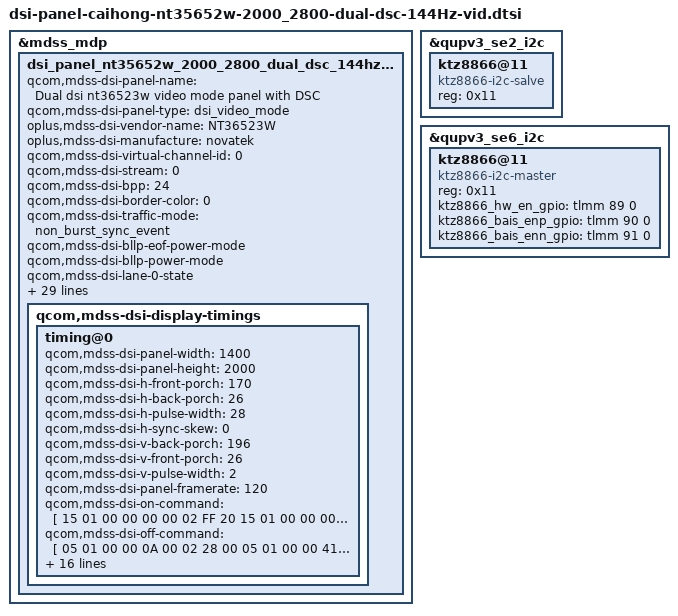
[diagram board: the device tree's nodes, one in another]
&mdss_mdp {
	dsi_panel_nt35652w_2000_2800_dual_dsc_144hz_vid: qcom,mdss_dsi_panel_nt35652w_2000_2800_dual_dsc_144hz_vid {
		qcom,mdss-dsi-panel-name = "Dual dsi nt36523w video mode panel with DSC";
		qcom,mdss-dsi-panel-type = "dsi_video_mode";
		oplus,mdss-dsi-vendor-name = "NT36523W";
		oplus,mdss-dsi-manufacture = "novatek";
		qcom,mdss-dsi-virtual-channel-id = <0>;
		qcom,mdss-dsi-stream = <0>;
		qcom,mdss-dsi-bpp = <24>;
		qcom,mdss-dsi-border-color = <0>;
		qcom,mdss-dsi-traffic-mode = "non_burst_sync_event";
		qcom,mdss-dsi-bllp-eof-power-mode;
		qcom,mdss-dsi-bllp-power-mode;
		qcom,mdss-dsi-lane-0-state;
		qcom,mdss-dsi-lane-1-state;
		qcom,mdss-dsi-lane-2-state;
		qcom,mdss-dsi-lane-3-state;
		qcom,mdss-dsi-dma-trigger = "trigger_sw";
		qcom,mdss-dsi-mdp-trigger = "none";
		qcom,mdss-dsi-tx-eot-append;
		qcom,mdss-dsi-reset-sequence = <1 10>, <0 5>, <1 10>;
		qcom,mdss-pan-physical-width-dimension = <240>;
		qcom,mdss-pan-physical-height-dimension = <171>;

		qcom,mdss-dsi-display-timings {
			timing@0 {
				qcom,mdss-dsi-panel-width = <1400>;
				qcom,mdss-dsi-panel-height = <2000>;
				qcom,mdss-dsi-h-front-porch = <170>;
				qcom,mdss-dsi-h-back-porch = <26>;
				qcom,mdss-dsi-h-pulse-width = <28>;
				qcom,mdss-dsi-h-sync-skew = <0>;
				qcom,mdss-dsi-v-back-porch = <196>;
				qcom,mdss-dsi-v-front-porch = <26>;
				qcom,mdss-dsi-v-pulse-width = <2>;
				qcom,mdss-dsi-panel-framerate = <120>;

				qcom,mdss-dsi-on-command = [
					15 01 00 00 00 00 02 FF 20
					15 01 00 00 00 00 02 FB 01
					15 01 00 00 00 00 02 62 36
					15 01 00 00 00 00 02 63 A4
					15 01 00 00 00 00 02 7C 22
					15 01 00 00 00 00 02 FF 23
					15 01 00 00 00 00 02 FB 01
					15 01 00 00 00 00 02 00 60
					15 01 00 00 00 00 02 07 20
					15 01 00 00 00 00 02 08 01
					15 01 00 00 00 00 02 09 5A
					15 01 00 00 00 00 02 10 0C
					15 01 00 00 00 00 02 11 03
					15 01 00 00 00 00 02 12 6B
					15 01 00 00 00 00 02 15 03
					15 01 00 00 00 00 02 16 10
					15 01 00 00 00 00 02 0A 8E
					15 01 00 00 00 00 02 0B 8E
					15 01 00 00 00 00 02 0C 8E
					15 01 00 00 00 00 02 0D 00
					15 01 00 00 00 00 02 19 00
					15 01 00 00 00 00 02 1A 04
					15 01 00 00 00 00 02 1B 08
					15 01 00 00 00 00 02 1C 0C
					15 01 00 00 00 00 02 1D 10
					15 01 00 00 00 00 02 1E 14
					15 01 00 00 00 00 02 1F 18
					15 01 00 00 00 00 02 20 1C
					15 01 00 00 00 00 02 21 20
					15 01 00 00 00 00 02 22 24
					15 01 00 00 00 00 02 23 28
					15 01 00 00 00 00 02 24 2C
					15 01 00 00 00 00 02 25 30
					15 01 00 00 00 00 02 26 34
					15 01 00 00 00 00 02 27 38
					15 01 00 00 00 00 02 28 3C
					15 01 00 00 00 00 02 2A 20
					15 01 00 00 00 00 02 2B 20
					15 01 00 00 00 00 02 30 FF
					15 01 00 00 00 00 02 31 FD
					15 01 00 00 00 00 02 32 FC
					15 01 00 00 00 00 02 33 FA
					15 01 00 00 00 00 02 34 F8
					15 01 00 00 00 00 02 35 F6
					15 01 00 00 00 00 02 36 F4
					15 01 00 00 00 00 02 37 F2
					15 01 00 00 00 00 02 38 F0
					15 01 00 00 00 00 02 39 EE
					15 01 00 00 00 00 02 3A EC
					15 01 00 00 00 00 02 3B EA
					15 01 00 00 00 00 02 3D E9
					15 01 00 00 00 00 02 3F E8
					15 01 00 00 00 00 02 40 E7
					15 01 00 00 00 00 02 41 E6
					15 01 00 00 00 00 02 45 FF
					15 01 00 00 00 00 02 46 F9
					15 01 00 00 00 00 02 47 F6
					15 01 00 00 00 00 02 48 F2
					15 01 00 00 00 00 02 49 F0
					15 01 00 00 00 00 02 4A EC
					15 01 00 00 00 00 02 4B E8
					15 01 00 00 00 00 02 4C E4
					15 01 00 00 00 00 02 4D E0
					15 01 00 00 00 00 02 4E DE
					15 01 00 00 00 00 02 4F D9
					15 01 00 00 00 00 02 50 D6
					15 01 00 00 00 00 02 51 D4
					15 01 00 00 00 00 02 52 C2
					15 01 00 00 00 00 02 53 D0
					15 01 00 00 00 00 02 54 CD
					15 01 00 00 00 00 02 58 FF
					15 01 00 00 00 00 02 59 F6
					15 01 00 00 00 00 02 5A F0
					15 01 00 00 00 00 02 5B EB
					15 01 00 00 00 00 02 5C E8
					15 01 00 00 00 00 02 5D E5
					15 01 00 00 00 00 02 5E E3
					15 01 00 00 00 00 02 5F E0
					15 01 00 00 00 00 02 60 DE
					15 01 00 00 00 00 02 61 DA
					15 01 00 00 00 00 02 62 D7
					15 01 00 00 00 00 02 63 D4
					15 01 00 00 00 00 02 64 D2
					15 01 00 00 00 00 02 65 D0
					15 01 00 00 00 00 02 66 CC
					15 01 00 00 00 00 02 67 C8
					15 01 00 00 00 00 02 FF 24
					15 01 00 00 00 00 02 FB 01
					15 01 00 00 00 00 02 1C 80
					15 01 00 00 00 00 02 3A 58
					15 01 00 00 00 00 02 3B 58
					15 01 00 00 00 00 02 5A 02
					15 01 00 00 00 00 02 5B 52
					39 01 00 00 00 00 03 5E 00 04
					39 01 00 00 00 00 04 92 64 01 0D
					15 01 00 00 00 00 02 98 80
					15 01 00 00 00 00 02 DB 73
					15 01 00 00 00 00 02 DE 08
					15 01 00 00 00 00 02 FF 25
					15 01 00 00 00 00 02 FB 01
					15 01 00 00 00 00 02 05 00
					15 01 00 00 00 00 02 1F 02
					15 01 00 00 00 00 02 20 52
					15 01 00 00 00 00 02 23 09
					15 01 00 00 00 00 02 24 1D
					15 01 00 00 00 00 02 26 02
					15 01 00 00 00 00 02 27 52
					15 01 00 00 00 00 02 2A 09
					15 01 00 00 00 00 02 2B 1D
					15 01 00 00 00 00 02 31 20
					15 01 00 00 00 00 02 3A 01
					15 01 00 00 00 00 02 42 0B
					15 01 00 00 00 00 02 68 04
					15 01 00 00 00 00 02 6A 00
					15 01 00 00 00 00 02 C0 0C
					15 01 00 00 00 00 02 C2 A5
					15 01 00 00 00 00 02 FF 26
					15 01 00 00 00 00 02 FB 01
					15 01 00 00 00 00 02 04 74
					39 01 00 00 00 00 05 19 1F 1E 1F 1F
					39 01 00 00 00 00 05 1A E5 C1 E5 E5
					39 01 00 00 00 00 05 1B 1F 1D 1F 1F
					39 01 00 00 00 00 05 1C 04 E1 04 04
					15 01 00 00 00 00 02 1E 64
					15 01 00 00 00 00 02 1F 64
					39 01 00 00 00 00 05 2A 1F 1E 1F 1F
					39 01 00 00 00 00 05 2B DC B9 DC DC
					15 01 00 00 00 00 02 2F 0B
					15 01 00 00 00 00 02 30 64
					15 01 00 00 00 00 02 32 64
					15 01 00 00 00 00 02 33 22
					15 01 00 00 00 00 02 34 92
					15 01 00 00 00 00 02 35 78
					15 01 00 00 00 00 02 36 96
					15 01 00 00 00 00 02 37 78
					15 01 00 00 00 00 02 38 06
					15 01 00 00 00 00 02 3A 64
					39 01 00 00 00 00 04 3D 00 A0 2A
					15 01 00 00 00 00 02 40 64
					15 01 00 00 00 00 02 41 64
					15 01 00 00 00 00 02 42 64
					15 01 00 00 00 00 02 45 0B
					15 01 00 00 00 00 02 46 64
					15 01 00 00 00 00 02 48 64
					15 01 00 00 00 00 02 4A 64
					15 01 00 00 00 00 02 4D 58
					15 01 00 00 00 00 02 4E 58
					15 01 00 00 00 00 02 51 02
					15 01 00 00 00 00 02 52 52
					15 01 00 00 00 00 02 56 02
					15 01 00 00 00 00 02 58 52
					15 01 00 00 00 00 02 5B 02
					15 01 00 00 00 00 02 5C 52
					39 01 00 00 00 00 04 84 1D 1D 1D
					39 01 00 00 00 00 05 99 23 23 23 23
					39 01 00 00 00 00 05 9A 97 97 97 97
					39 01 00 00 00 00 05 9B 22 22 22 22
					39 01 00 00 00 00 05 9C B5 B5 B5 B5
					39 01 00 00 00 00 05 9D 23 23 23 23
					39 01 00 00 00 00 05 9E 8D 8D 8D 8D
					15 01 00 00 00 00 02 A7 08
					15 01 00 00 00 00 02 FF 27
					15 01 00 00 00 00 02 FB 01
					15 01 00 00 00 00 02 30 F0
					15 01 00 00 00 00 02 31 2A
					15 01 00 00 00 00 02 76 F0
					15 01 00 00 00 00 02 77 02
					15 01 00 00 00 00 02 79 13
					39 01 00 00 00 00 03 80 C0 08
					39 01 00 00 00 00 03 81 2D 00
					39 01 00 00 00 00 03 82 A5 80
					39 01 00 00 00 00 03 84 5F 00
					39 01 00 00 00 00 03 85 28 00
					39 01 00 00 00 00 03 86 A5 80
					39 01 00 00 00 00 03 88 5F 00
					15 01 00 00 00 00 02 96 F0
					15 01 00 00 00 00 02 97 2A
					15 01 00 00 00 00 02 FF 2A
					15 01 00 00 00 00 02 FB 01
					15 01 00 00 00 00 02 14 09
					15 01 00 00 00 00 02 1E 09
					15 01 00 00 00 00 02 1F 09
					15 01 00 00 00 00 02 64 36
					15 01 00 00 00 00 02 67 3E
					15 01 00 00 00 00 02 6A 36
					15 01 00 00 00 00 02 6D 36
					15 01 00 00 00 00 02 70 36
					15 01 00 00 00 00 02 73 36
					15 01 00 00 00 00 02 76 36
					15 01 00 00 00 00 02 79 3E
					15 01 00 00 00 00 02 7C 36
					15 01 00 00 00 00 02 7F 36
					15 01 00 00 00 00 02 82 36
					15 01 00 00 00 00 02 85 3E
					15 01 00 00 00 00 02 88 3E
					15 01 00 00 00 00 02 8B 36
					15 01 00 00 00 00 02 8E 36
					15 01 00 00 00 00 02 91 36
					15 01 00 00 00 00 02 94 36
					39 01 00 00 00 00 04 9F 36 00 00
					39 01 00 00 00 00 04 A0 36 00 00
					15 01 00 00 00 00 02 A3 00
					39 01 00 00 00 00 04 B3 36 00 00
					15 01 00 00 00 00 02 C4 02
					15 01 00 00 00 00 02 C5 09
					15 01 00 00 00 00 02 C6 1D
					15 01 00 00 00 00 02 C8 0B
					39 01 00 00 00 00 07 CC A5 5A 00 55 00 00
					15 01 00 00 00 00 02 D0 84
					15 01 00 00 00 00 02 FF 10
					15 01 00 00 00 00 02 FB 01
					39 01 00 00 00 00 03 51 07 FF
					15 01 00 00 00 00 02 53 2C
					15 01 00 00 00 00 02 B9 00
					15 01 00 00 00 00 02 55 00
					15 01 00 00 00 00 02 B9 02
					39 01 00 00 00 00 07 3B 03 C6 1A 0A 0A 00
					15 01 00 00 00 00 02 90 03
					39 01 00 00 00 00 11 91 89 A8 00 14 D2 00 02 7D 02 0E 00 09 05 7A 03 DC
					39 01 00 00 00 00 03 92 10 D0
					15 01 00 00 00 00 02 9D 01
					15 01 00 00 00 00 02 B2 91
					15 01 00 00 00 00 02 B3 40
					15 01 00 00 00 00 02 FF 10
					15 01 00 00 00 00 02 FB 01

					05 01 00 00 78 00 02 11 00
					05 01 00 00 0A 00 02 29 00
				];
				qcom,mdss-dsi-off-command = [
					05 01 00 00 0A 00 02 28 00
					05 01 00 00 41 00 02 10 00
				];
				qcom,mdss-dsi-on-command-state = "dsi_lp_mode";
				qcom,mdss-dsi-off-command-state = "dsi_lp_mode";
				qcom,mdss-dsi-h-sync-pulse = <0>;
				qcom,compression-mode = "dsc";
				qcom,mdss-dsc-version = <0x12>;
				qcom,mdss-dsc-encoders = <1>;
				qcom,mdss-dsc-slice-height = <20>;
				qcom,mdss-dsc-slice-width = <700>;
				qcom,mdss-dsc-slice-per-pkt = <2>;
				qcom,mdss-dsc-bit-per-component = <8>;
				qcom,mdss-dsc-bit-per-pixel = <8>;
				qcom,mdss-dsc-block-prediction-enable;
			};
		};
	};
};

&dsi_panel_nt35652w_2000_2800_dual_dsc_144hz_vid {
	qcom,panel-supply-entries = <&oplus_dsi_panel_custom_pwr_supply>;
	qcom,dsi-ctrl-num = <0 1>;
	qcom,dsi-phy-num = <0 1>;
	qcom,dsi-select-clocks = "pll_byte_clk0", "pll_dsi_clk0";
	qcom,mdss-dsi-bl-pmic-control-type = "bl_ctrl_external";
	qcom,mdss-dsi-bl-min-level = <10>;
	qcom,mdss-dsi-bl-max-level = <2047>;
	qcom,mdss-brightness-max-level = <2047>;
	qcom,mdss-dsi-bl-inverted-dbv;
	qcom,platform-reset-gpio = <&tlmm 133 0>;
	qcom,esd-check-enabled;
	qcom,mdss-dsi-panel-status-check-mode = "error_flag";
	qcom,error-flag-gpio = <&tlmm 86 0>;
	qcom,error-flag-gpio-slave = <&tlmm 43 0>;
	oplus,bl-use-ktz8866-ic-ctrl;
	oplus,dp-enabled;

	qcom,mdss-dsi-display-timings {
		timing@0 {
			qcom,mdss-dsi-panel-phy-timings = [00 24 0A 0A 1A 18 0A
				0A 09 02 04 00 1E 0F];
			qcom,display-topology = <2 2 2>;
			qcom,default-topology-index = <0>;
		};
	};
};

&qupv3_se2_i2c {
	status = "ok";
	ktz8866@11 {
		compatible = "ktz8866-i2c-salve";
		reg = <0x11>;
	};
};

&qupv3_se6_i2c {
	status = "ok";
	ktz8866@11 {
		compatible = "ktz8866-i2c-master";
		reg = <0x11>;
		ktz8866_hw_en_gpio = <&tlmm 89 0>;
		ktz8866_bais_enp_gpio = <&tlmm 90 0>;
		ktz8866_bais_enn_gpio = <&tlmm 91 0>;
	};
};
